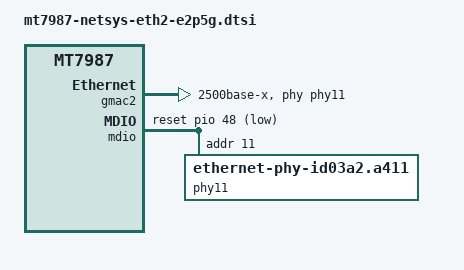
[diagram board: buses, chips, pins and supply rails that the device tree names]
// SPDX-License-Identifier: (GPL-2.0 OR MIT)

&eth {
	gmac2: mac@2 {
		compatible = "mediatek,eth-mac";
		reg = <2>;
		pcs-handle = <&sgmiipcs1>;
		phy-mode = "2500base-x";
		phy-handle = <&phy11>;
	};
};

&hnat {
	mtketh-lan2 = "eth2";
	mtketh-max-gmac = <3>;
};

&mdio {
	/* move phy reset-gpio from &phy11 to make sure reset sequence */
	reset-gpios = <&pio 48 1>;
	reset-delay-us = <10000>;

	phy11: phy@11 {
		compatible = "ethernet-phy-id03a2.a411";
		reg = <11>;
		phy-mode = "2500base-x";
		airoha,polarity = <1>;
		airoha,surge = <0>;
		airoha,phy-handle;
	};
};
